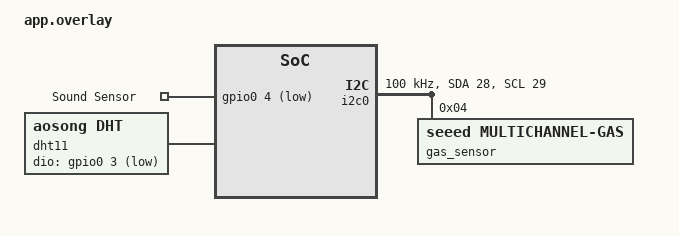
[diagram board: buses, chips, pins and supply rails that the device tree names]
/ {
    /* This is a container for input devices */
    sound_sensor_group {
        compatible = "gpio-keys";
        
        /* The actual node your C code will look for */
        sound_node: sound_node_0 {
            gpios = <&gpio0 4 (GPIO_PULL_UP | GPIO_ACTIVE_LOW)>;
            label = "Sound Sensor";
        };
    };  
};

/ {
    dht11: dht11 {
        compatible = "aosong,dht";
        status = "okay";
        dio-gpios = <&gpio0 3 (GPIO_PULL_UP | GPIO_ACTIVE_LOW)>;
    };
};

&i2c0 {
    status = "okay";
    scl-pin = <29>;
    sda-pin = <28>;
    clock-frequency = <I2C_BITRATE_STANDARD>;
    gas_sensor: gas_sensor@4 {
        compatible = "seeed,multichannel-gas";
        reg = <0x04>;
    };
};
